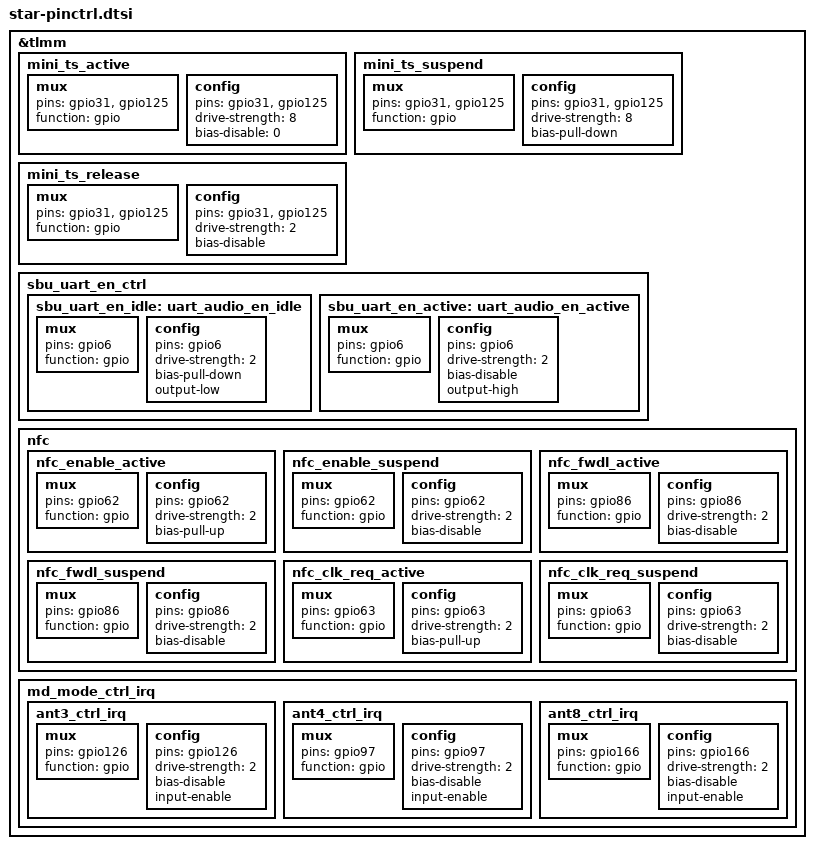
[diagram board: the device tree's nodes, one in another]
/*for star pinctrl */
&tlmm {
	/* cyttsp5 touchscreen pins */
	/* irq: gpio31, rst: gpio17 */
	mini_ts_active: mini_ts_active {
		mux {
			pins = "gpio31", "gpio125";
			function = "gpio";
		};

		config {
			pins = "gpio31", "gpio125";
			drive-strength = <8>;
			bias-disable = <0>;
		};
	};

	mini_ts_suspend: mini_ts_suspend {
		mux {
			pins = "gpio31", "gpio125";
			function = "gpio";
		};

		config {
			pins = "gpio31", "gpio125";
			drive-strength = <8>;
			bias-pull-down;
		};
	};

	mini_ts_release: mini_ts_release {
		mux {
			pins = "gpio31", "gpio125";
			function = "gpio";
		};

		config {
			pins = "gpio31", "gpio125";
			drive-strength = <2>;
			bias-disable;
		};
	};

	sbu_uart_en_ctrl {
		sbu_uart_en_idle: uart_audio_en_idle {
			mux {
				pins = "gpio6";
				function = "gpio";
			};
			config {
				pins = "gpio6";
				drive-strength = <2>;
				bias-pull-down;
				output-low;
			};
		};

		sbu_uart_en_active: uart_audio_en_active {
			mux {
				pins = "gpio6";
				function = "gpio";
			};
			config {
				pins = "gpio6";
				drive-strength = <2>;
				bias-disable;
				output-high;
			};
		};
	};

	nfc {
			nfc_enable_active: nfc_enable_active {
				mux {
					pins = "gpio62";
					function = "gpio";
				};

				config {
					pins = "gpio62";
					drive-strength = <2>; /* 2 MA */
					bias-pull-up;
				};
			};

			nfc_enable_suspend: nfc_enable_suspend {
				mux {
					pins = "gpio62";
					function = "gpio";
				};

				config {
					pins = "gpio62";
					drive-strength = <2>; /* 2 MA */
					bias-disable;
				};
			};

			nfc_fwdl_active: nfc_fwdl_active {
				mux {
					/* 86: Firmware */
					pins = "gpio86";
					function = "gpio";
				};

				config {
					pins = "gpio86";
					drive-strength = <2>; /* 2 MA */
					bias-disable;
				};
			};

			nfc_fwdl_suspend: nfc_fwdl_suspend {
				mux {
					/*86: Firmware */
					pins = "gpio86";
					function = "gpio";
				};

				config {
					pins = "gpio86";
					drive-strength = <2>; /* 2 MA */
					bias-disable;
				};
			};

			nfc_clk_req_active: nfc_clk_req_active {
				/* active state */
				mux {
					/* GPIO 63: NFC CLOCK REQUEST */
					pins = "gpio63";
					function = "gpio";
				};

				config {
					pins = "gpio63";
					drive-strength = <2>; /* 2 MA */
					bias-pull-up;
				};
			};

			nfc_clk_req_suspend: nfc_clk_req_suspend {
				/* sleep state */
				mux {
					/* GPIO 63: NFC CLOCK REQUEST */
					pins = "gpio63";
					function = "gpio";
				};

				config {
					pins = "gpio63";
					drive-strength = <2>; /* 2 MA */
					bias-disable;
				};
			};
	};

    md_mode_ctrl_irq {
		ant3_ctrl_irq: ant3_ctrl_irq {
			mux {
				pins = "gpio126";
				function = "gpio";
			};

			config {
				pins = "gpio126";
				drive-strength = <2>;
				bias-disable;
				input-enable;
			};
		};

		ant4_ctrl_irq: ant4_ctrl_irq {
			mux {
				pins = "gpio97";
				function = "gpio";
			};

			config {
				pins = "gpio97";
				drive-strength = <2>;
				bias-disable;
				input-enable;
			};
		};

		ant8_ctrl_irq: ant8_ctrl_irq {
			mux {
				pins = "gpio166";
				function = "gpio";
			};

			config {
				pins = "gpio166";
				drive-strength = <2>;
				bias-disable;
				input-enable;
			};
		};
	};
};
